# MU3E_FULL8LANE_TYPE0_SYSTEM_SC_HUB register map
Vendor: Mu3e; Series: MU3E_FULL8LANE_TYPE0; File version: 2026.05.06
Registers are 32-bit, read-write, reset 0x0 unless marked. A register's access mark holds for its fields unless they carry their own. Offsets are from the block's base; [hi:lo] are bit positions.

## DATA_PATH_SUBSYSTEM_LVDS_RX_CONTROLLER_PRO_0_CSR — Datapath-local slave expanded below the SC-hub mm_bridge.s0 aperture. Qsys slave data_path_subsystem_lvds_rx_controller_pro_0.csr is SC-hub-relative at 0x00029000 with compiled aperture size 0x00001000. Compiled Qsys module lvds_rx_controller_pro_0 kind=mu3e_lvds_controller version=26.2.1.506 from full8lane_type0_datapath.qsys. Version/identity parameters: VERSION_MAJOR=26, VERSION_MINOR=2, VERSION_PATCH=1, BUILD=1286, VERSION_DATE=539362566, VERSION_GIT=0, IP_UID=1280722003, INSTANCE_ID=0, N_LANE=9, N_ENGINE=1, ROUTING_TOPOLOGY=1, SCORE_WINDOW_W=10, SCORE_ACCEPT=8, SCORE_REJECT=2. The Qsys module version is the normalized LVDS IP release; Qsys shows BUILD=1286 and VERSION_DATE=539362566 because the Tcl build supplied hex literals BUILD=0x506 and VERSION_DATE=0x20260506. Standalone source SVD mu3e_lvds_controller/lvds_rx_controller_pro.svd version 26.2.1.0506 is generated from the same current SV RTL map. This system SVD emits the LVDS peripheral directly from mu3e_lvds_controller/rtl/mu3e_lvds_controller.sv so the SC-hub-specific Qsys version and address notes stay local to the grouped map.
Base 0x00029000
0x00 UID ro reset 0x4C564453 — Software-visible LVDS controller UID. Default ASCII "LVDS" (0x4C564453).
  [31:0] value — Compile-time or integration-time LVDS UID word.
0x04 META — Read-multiplexed metadata word. Write page[1:0] before reading back: 0=VERSION, 1=VERSION_DATE, 2=VERSION_GIT, 3=INSTANCE_ID.
  [1:0] page — Selects the metadata read page.
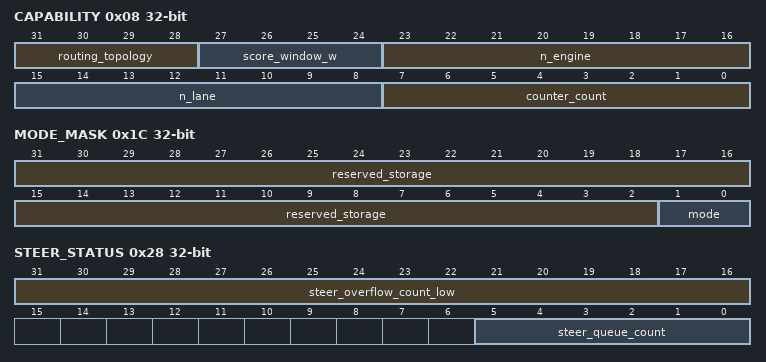
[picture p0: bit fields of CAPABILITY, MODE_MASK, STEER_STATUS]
0x08 CAPABILITY ro — Packed capability word for the compiled lane/engine/routing profile.
  [31:28] routing_topology — Compiled routing topology selector.
  [27:24] score_window_w — Score-window width used by the engine steering score saturators.
  [23:16] n_engine — Number of shared decode engines after RTL parameter clamping.
  [15:8] n_lane — Number of active LVDS lanes after RTL parameter clamping.
  [7:0] counter_count — Number of per-lane counters exposed through the selected-lane counter window.
0x0C SYNC_PATTERN — Training/control symbol accepted as the lane synchronization pattern. Writes are accepted only for RTL-recognized K28.5/K28.0/K23.7 encodings.
  [9:0] pattern — 10-bit synchronization symbol.
0x10 LANE_GO — Per-lane enable mask, clipped by the compiled active-lane mask.
  [31:0] lane_mask — One bit per physical LVDS lane.
0x14 DPA_HOLD — Per-lane DPA hold request mask, clipped by the compiled active-lane mask.
  [31:0] lane_mask — One bit per physical LVDS lane.
0x18 SOFT_RESET — Per-lane soft-reset request latch. Writing 1 requests a lane soft reset; RTL clears the bit after the hold interval completes.
  [31:0] lane_mask — One bit per physical LVDS lane.
0x1C MODE_MASK — Global two-bit lane mode in the current RTL. The full word is stored, but lane_mode() currently consumes bits [1:0].
  [31:2] reserved_storage — Stored by RTL for future per-lane mode expansion; currently not decoded by lane_mode().
  [1:0] mode — 0=bitslipping, 1=adapting, 2=autoing.
0x20 SCORE_ACCEPT — Engine steering accept threshold, clamped by the RTL score window.
  [15:0] threshold — Accept threshold.
0x24 SCORE_REJECT — Engine steering reject threshold, clamped not to exceed SCORE_ACCEPT.
  [15:0] threshold — Reject threshold.
0x28 STEER_STATUS ro — Snapshot status from the data-clock steering queue. This read may wait while the control clock requests the data-clock snapshot.
  [31:16] steer_overflow_count_low — Low 16 bits of the saturating steering-queue overflow counter.
  [5:0] steer_queue_count — Current queued engine-steering decisions.
0x40 LANE_SELECT — Selected lane for the counter snapshot window. Writes above the last active lane clamp to the last active lane.
  [5:0] lane — Zero-based lane index for counter snapshot reads.
0x44 CODE_VIOLATIONS ro — Illegal or unexpected 8b/10b symbol events observed on the selected lane. The lane is selected by LANE_SELECT and the value is returned through the RTL snapshot path.
  [31:0] value — Selected-lane saturating counter value.
0x48 DISP_VIOLATIONS ro — Disparity violation events observed on the selected lane. The lane is selected by LANE_SELECT and the value is returned through the RTL snapshot path.
  [31:0] value — Selected-lane saturating counter value.
0x4C COMMA_LOSSES ro — Selected-lane comma/sync-pattern loss events. The lane is selected by LANE_SELECT and the value is returned through the RTL snapshot path.
  [31:0] value — Selected-lane saturating counter value.
0x50 BITSLIP_EVENTS ro — Selected-lane bitslip control events. The lane is selected by LANE_SELECT and the value is returned through the RTL snapshot path.
  [31:0] value — Selected-lane saturating counter value.
0x54 DPA_UNLOCKS ro — Selected-lane DPA unlock events. The lane is selected by LANE_SELECT and the value is returned through the RTL snapshot path.
  [31:0] value — Selected-lane saturating counter value.
0x58 REALIGNS ro — Selected-lane realignment events. The lane is selected by LANE_SELECT and the value is returned through the RTL snapshot path.
  [31:0] value — Selected-lane saturating counter value.
0x5C SCORE_CHANGES ro — Selected-lane engine-score change events. The lane is selected by LANE_SELECT and the value is returned through the RTL snapshot path.
  [31:0] value — Selected-lane saturating counter value.
0x60 ENGINE_STEER ro — Selected-lane engine steering decisions. The lane is selected by LANE_SELECT and the value is returned through the RTL snapshot path.
  [31:0] value — Selected-lane saturating counter value.
0x64 SOFT_RESETS ro — Selected-lane soft-reset completions. The lane is selected by LANE_SELECT and the value is returned through the RTL snapshot path.
  [31:0] value — Selected-lane saturating counter value.
0x68 UPTIME ro — Selected-lane uptime counter in data-clock cycles. The lane is selected by LANE_SELECT and the value is returned through the RTL snapshot path.
  [31:0] value — Selected-lane saturating counter value.
